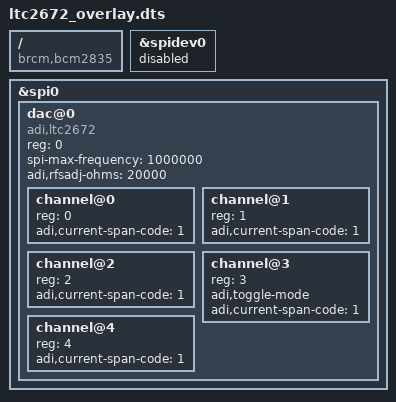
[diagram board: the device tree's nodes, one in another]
/dts-v1/;
/plugin/;

/ {
	compatible = "brcm,bcm2835", "brcm,bcm2708", "brcm,bcm2709";
};

&spidev0 {
	status = "disabled";
};

&spi0 {
	#address-cells = <1>;
	#size-cells = <0>;
	status = "okay";

	dac@0 {
		compatible = "adi,ltc2672";
		reg = <0>;
		spi-max-frequency = <1000000>;

                adi,rfsadj-ohms = <20000>;

		#address-cells = <1>;
		#size-cells = <0>;

                channel@0 {
                        reg = <0>;
                        adi,current-span-code = <1>;
                };

                channel@1 {
                        reg = <1>;
                        adi,current-span-code = <1>;
                };

                channel@2 {
                        reg = <2>;
                        adi,current-span-code = <1>;
                };

                channel@3 {
                        reg = <3>;
                        adi,toggle-mode;
                        adi,current-span-code = <1>;
                };

                channel@4 {
                        reg = <4>;
                        adi,current-span-code = <1>;
                };
	};
};
